# Special_Function_18 register map
Vendor: Texas Instruments
Peripheral module from a debugger description file (folder msp430).
Registers are 8-bit, read-write, reset 0x0 unless marked. A register's access mark holds for its fields unless they carry their own. Offsets are as the file gives them; lines under a group give offsets from that group; [hi:lo] are bit positions; {n}, {i} and the like mark numbered series; 'fields as' and 'values as' point back to an identical list; <NAME> marks a mode.

## Special_Function
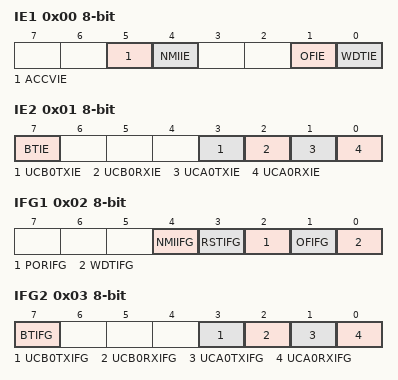
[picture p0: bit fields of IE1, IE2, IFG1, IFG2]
0x00 IE1 — Interrupt Enable 1
  [5] ACCVIE, [4] NMIIE, [1] OFIE, [0] WDTIE
0x01 IE2 — Interrupt Enable 2
  [7] BTIE, [3] UCB0TXIE, [2] UCB0RXIE, [1] UCA0TXIE, [0] UCA0RXIE
0x02 IFG1 — Interrupt Flag 1
  [4] NMIIFG, [3] RSTIFG, [2] PORIFG, [1] OFIFG, [0] WDTIFG
0x03 IFG2 — Interrupt Flag 2
  [7] BTIFG, [3] UCB0TXIFG, [2] UCB0RXIFG, [1] UCA0TXIFG, [0] UCA0RXIFG
